# NUC100DN_v1 register map
File version: 1.0
Registers are 32-bit, read-write, reset 0x0 unless marked. A register's access mark holds for its fields unless they carry their own. Offsets are from the block's base; [hi:lo] are bit positions.

## SCS — SCS Register Map
Base 0xE000ED00
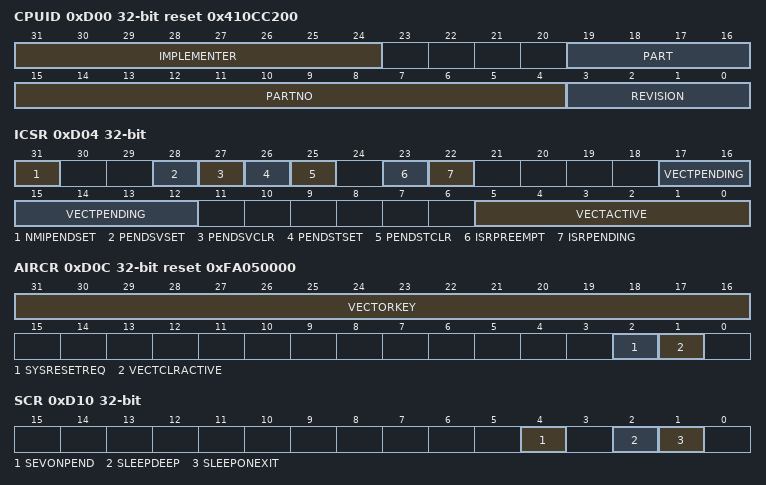
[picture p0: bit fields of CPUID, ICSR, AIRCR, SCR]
0xD00 CPUID ro reset 0x410CC200
  [31:24] IMPLEMENTER
  [19:16] PART — Read as 0xC for ARMv6-M parts
  [15:4] PARTNO — Read as 0xC20.
  [3:0] REVISION — Read as 0x0
0xD04 ICSR — Interrupt Control and State Register
  [31] NMIPENDSET — NMI Set-pending Bit. Write: Note: Because NMI is the highest-priority exception, normally the processor enters the NMI exception handler as soon as it detects a write of 1 to this bit. Entering the handler then clears this bit to 0. This means a read of this bit by the NMI exception handler returns 1 only if the NMI signal is reasserted while the processor is executing that handler.
    0=No effect. NMI exception not pending; 1=Changes NMI exception state to pending. NMI exception pending
  [28] PENDSVSET — PendSV Set-pending Bit. Write: Note: Writing 1 to this bit is the only way to set the PendSV exception state to pending.
    0=No effect. PendSV exception is not pending; 1=Changes PendSV exception state to pending. PendSV exception is pending
  [27] PENDSVCLR — PendSV Clear-pending Bit. Write: Note: This is a write only bit. When you want to clear PENDSV bit, you must "write 0 to PENDSVSET and write 1 to PENDSVCLR" at the same time.
    0=No effect; 1=Removes the pending state from the PendSV exception
  [26] PENDSTSET — SysTick Exception Set-pending Bit. Write:
    0=No effect. SysTick exception is not pending; 1=Changes SysTick exception state to pending. SysTick exception is pending
  [25] PENDSTCLR — SysTick Exception Clear-pending Bit. Write: Note: This is a write only bit. When you want to clear PENDST bit, you must "write 0 to PENDSTSET and write 1 to PENDSTCLR" at the same time.
    0=No effect; 1=Removes the pending state from the SysTick exception
  [23] ISRPREEMPT — If Set, a Pending Exception Will Be Serviced on Exit From the Debug Halt State. This bit is read only.
  [22] ISRPENDING — Interrupt Pending Flag, Excluding NMI and Faults: Note: This bit is read only.
    0=Interrupt not pending; 1=Interrupt pending
  [17:12] VECTPENDING — Indicates the Exception Number of the Highest Priority Pending Enabled Exception:
    0=No pending exceptions
  [5:0] VECTACTIVE — Contains the Active Exception Number
    0=Thread mode
0xD0C AIRCR reset 0xFA050000 — Application Interrupt and Reset Control Register
  [31:16] VECTORKEY — When writing this register, this field should be 0x05FA, otherwise the write action will be unpredictable.
  [2] SYSRESETREQ — System Reset Request. Writing this bit to 1 will cause a reset signal to be asserted to the chip to indicate a reset is requested. The bit is a write only bit and self-clears as part of the reset sequence.
  [1] VECTCLRACTIVE — Exception Active Status Clear Bit. Setting this bit to 1 will clear all active state information for fixed and configurable exceptions. The bit is a write only bit and can only be written when the core is halted. Note: It is the debugger's responsibility to re-initialize the stack.
0xD10 SCR — System Control Register
  [4] SEVONPEND — Send Event on Pending Bit: When an event or interrupt enters pending state, the event signal wakes up the processor from WFE. If the processor is not waiting for an event, the event is registered and affects the next WFE. The processor also wakes up on execution of an SEV instruction or an external event.
    0=Only enabled interrupts or events can wake-up the processor, disabled interrupts are excluded; 1=Enabled events and all interrupts, including disabled interrupts, can wake-up the processor
  [2] SLEEPDEEP — Controls Whether the Processor Uses Sleep or Deep Sleep As Its Low Power Mode:
    0=Sleep; 1=Deep sleep
  [1] SLEEPONEXIT — Indicates Sleep-on-exit When Returning From Handler Mode to Thread Mode: Setting this bit to 1 enables an interrupt driven application to avoid returning to an empty main application.
    0=Do not sleep when returning to Thread mode; 1=Enter sleep, or deep sleep, on return from an ISR to Thread mode
0xD1C SHPR2 — System Handler Priority Register 2
  [31:30] PRI_11 — Priority of System Handler 11 - SVCall "0" denotes the highest priority and "3" denotes the lowest priority
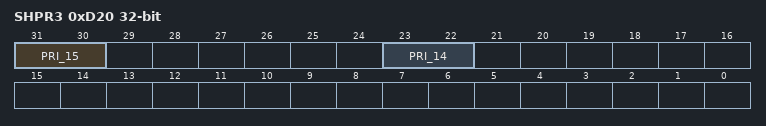
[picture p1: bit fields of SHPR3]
0xD20 SHPR3 — System Handler Priority Register 3
  [31:30] PRI_15 — Priority of System Handler 15 - SysTick "0" denotes the highest priority and "3" denotes the lowest priority
  [23:22] PRI_14 — Priority of System Handler 14 - PendSV "0" denotes the highest priority and "3" denotes the lowest priority
